# max32665 register map
Vendor: Maxim-Integrated; Series: ARMCM3; File version: 1.0
CPU: CM4 r2p1, little endian, MPU, FPU, 3 interrupt priority bits
Registers are 32-bit, read-write, reset 0x0 unless marked. A register's access mark holds for its fields unless they carry their own. Offsets are from the block's base; [hi:lo] are bit positions; {n}, {i} and the like mark numbered series; 'fields as' and 'values as' point back to an identical list.

## GCR — Global Control Registers.
Base 0x40000000
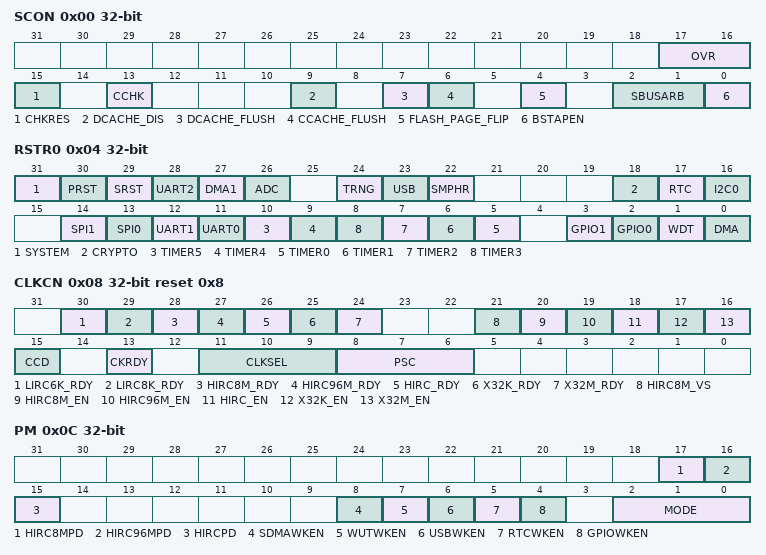
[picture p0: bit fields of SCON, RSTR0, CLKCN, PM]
0x00 SCON (reset mask 0xFFFFFFFE) — System Control.
  [17:16] OVR — Operating Voltage Range. Setting these bits according to the VCore voltage allows the on-chip Random-Access memories to operate in their optimal timing range.
    0=0_9V (0.9V +/- 10%); 1=1_0V (1.0V +/- 10%); 2=1_1V (1.1V +/- 10%)
  [15] CHKRES — ROM Checksum Result. This bit is only valid when CHKRD=1.
    0=pass (ROM Checksum Correct.); 1=fail (ROM Checksum Fail.)
  [13] CCHK — Compute ROM Checksum. This bit is self-cleared when calculation is completed. Once set, software clearing this bit is ignored and the bit will remain set until the operation is completed.
    0=complete (No operation/complete.); 1=Start operation
  [9] DCACHE_DIS — Data Cache Disable. The system cache(s) will be completely disabled when this bit is set.
    0=en (Is enabled.); 1=dis (Is Disabled.)
  [7] DCACHE_FLUSH — Data Cache Flush. The system cache(s) will be flushed when this bit is set.
    0=Normal System Cache Operation; 1=flush (System Cache is flushed)
  [6] CCACHE_FLUSH — Code Cache Flush. This bit is used to flush the code caches and the instruction buffer of the Cortex-M4.
    0=Normal Code Cache Operation; 1=flush (Code Caches and CPU instruction buffer are flushed)
  [4] FLASH_PAGE_FLIP — Flips the Flash bottom and top halves. (Depending on the total flash size, each half is either 256K or 512K). Initiating a flash page flip will cause a flush of both the data buffer on the DCODE bus and the internal instruction buffer.
    0=normal (Physical layout matches logical layout.); 1=swapped (Bottom half mapped to logical top half and vice versa.)
  [2:1] SBUSARB — System bus abritration scheme. These bits are used to select between Fixed-burst abritration and Round-Robin scheme. The Round-Robin scheme is selected by default. These bits are reset by the system reset.
    0=fix (Fixed Burst abritration.); 1=Round-robin scheme
  [0] BSTAPEN — Boundary Scan TAP enable. When enabled, the JTAG port is connected to the Boundary Scan TAP. Otherwise, the port is connected to the ARM ICE function. This bit is reset by the POR. Reset value and access depend on the part number.
    0=dis (Boundary Scan TAP port disabled.); 1=en (Boundary Scan TAP port enabled.)
0x04 RSTR0 — Reset.
  [all] fields
    0=reset_done (Reset complete.); 1=busy (Starts Reset or indicates reset in progress.)
  [31] SYSTEM — System Reset. Setting this bit to 1 resets the CPU core and all peripherals, including the watchdog timer.
  [30] PRST — Peripheral Reset. Setting this bit to 1 resets all peripherals. The CPU core, the watchdog timer, and all GPIO pins are unaffected by this reset.
  [29] SRST — Soft Reset. Setting this bit to 1 resets everything except the CPU and the watchdog timer.
  [28] UART2 — UART2 Reset. Setting this bit to 1 resets all UART 2 blocks.
  [27] DMA1 — DMA 1 Reset.
  [26] ADC — Analog to Digital Reset.
  [24] TRNG — TRNG Reset.
  [23] USB — USB Reset. Setting this bit resets both USB blocks.
  [22] SMPHR — SMPHR Reset. Setting this bit to 1 resets the SMPHR block.
  [18] CRYPTO — Cryptographic Reset. Setting this bit to 1 resets the AES block, the SHA block and the DES block.
  [17] RTC — Real Time Clock Reset.
  [16] I2C0 — I2C0 Reset.
  [14] SPI1 — SPI1 Reset. Setting this bit to 1 resets all SPI 1 blocks.
  [13] SPI0 — SPI0 Reset. Setting this bit to 1 resets all SPI 0 blocks.
  [12] UART1 — UART1 Reset. Setting this bit to 1 resets all UART 1 blocks.
  [11] UART0 — UART0 Reset. Setting this bit to 1 resets all UART 0 blocks.
  [10] TIMER5 — Timer3 Reset. Setting this bit to 1 resets Timer 5 blocks.
  [9] TIMER4 — Timer3 Reset. Setting this bit to 1 resets Timer 4 blocks.
  [n+5] TIMER{n} (n=0..3) — Timer{n} Reset. Setting this bit to 1 resets Timer {n} blocks.
  [3] GPIO1 — GPIO1 Reset. Setting this bit to 1 resets GPIO1 pins to their default states.
  [2] GPIO0 — GPIO0 Reset. Setting this bit to 1 resets GPIO0 pins to their default states.
  [1] WDT — Watchdog Timer Reset.
  [0] DMA — DMA Reset.
0x08 CLKCN reset 0x8 — Clock Control.
  [30] LIRC6K_RDY ro — 6kHz Low Frequency Reference Clock Ready.
    0=not (Is not Ready.); 1=ready (Is Ready.)
  [29] LIRC8K_RDY ro — 8kHz Low Frequency Reference Clock Ready.
    0=not (Is not Ready.); 1=ready (Is Ready.)
  [28] HIRC8M_RDY ro — 8MHz HIRC Ready.
    0=not (Is not Ready.); 1=ready (Is Ready.)
  [27] HIRC96M_RDY ro — 96MHz HIRC Ready.
    0=not (Is not Ready.); 1=ready (Is Ready.)
  [26] HIRC_RDY ro — 60MHz HIRC Ready.
    0=not (Is not Ready.); 1=ready (Is Ready.)
  [25] X32K_RDY ro — 32kHz Crystal Oscillator Ready
    0=not (Is not Ready.); 1=ready (Is Ready.)
  [24] X32M_RDY ro — 32MHz Crystal Oscillator Ready
    0=not (Is not Ready.); 1=ready (Is Ready.)
  [21] HIRC8M_VS — 8MHz High Frequency Internal Reference Clock Voltage Select. This register bit is used to select the power supply to the HIRC8M.
    0=VCore Supply; 1=1V (Dedicated 1v regulated supply.)
  [20] HIRC8M_EN — 8MHz High Frequency Internal Reference Clock Enable.
    0=dis (Is Disabled.); 1=en (Is Enabled.)
  [19] HIRC96M_EN — 96MHz High Frequency Internal Reference Clock Enable.
    0=dis (Is Disabled.); 1=en (Is Enabled.)
  [18] HIRC_EN — 60MHz High Frequency Internal Reference Clock Enable.
    0=dis (Is Disabled.); 1=en (Is Enabled.)
  [17] X32K_EN — 32kHz Crystal Oscillator Enable.
    0=dis (Is Disabled.); 1=en (Is Enabled.)
  [16] X32M_EN — 32MHz Crystal Oscillator Enable.
    0=dis (Is Disabled.); 1=en (Is Enabled.)
  [15] CCD ro — Cryptographic clock divider
    0=non_div (The cryptographic accelerator clock is running in non-divided mode.); 1=div (The cryptographic accelerator clock is running in divided mode.)
  [13] CKRDY ro — Clock Ready. This read only bit reflects whether the currently selected system clock source is running.
    0=busy (Switchover to the new clock source (as selected by CLKSEL) has not yet occurred.); 1=ready (System clock running from CLKSEL clock source.)
  [11:9] CLKSEL — Clock Source Select. This 3 bit field selects the source for the system clock.
    0=HIRC (HIRC Clock); 2=XTAL32M (32MHz Crystal is used for the system clock.); 3=LIRC8 (8kHz LIRC is used for the system clock.); 4=HIRC96 (The internal 96 MHz oscillator is used for the system clock.); 5=HIRC8 (The internal 8 MHz oscillator is used for the system clock.); 6=XTAL32k (32kHz is used for the system clock.)
  [8:6] PSC — Prescaler Select. This 3 bit field sets the system operating frequency by controlling the prescaler that divides the output of the PLL0.
    0=div1 (Divide by 1.); 1=div2 (Divide by 2.); 2=div4 (Divide by 4.); 3=div8 (Divide by 8.); 4=div16 (Divide by 16.); 5=div32 (Divide by 32.); 6=div64 (Divide by 64.); 7=div128 (Divide by 128.)
0x0C PM — Power Management.
  [17] HIRC8MPD — 8MHz power down. This bit selects 8MHz HIRC power state in DEEPSLEEP mode.
    0=active (Mode is Active.); 1=deepsleep (Powered down in DEEPSLEEP.)
  [16] HIRC96MPD — 96MHz power down. This bit selects 96MHz HIRC power state in DEEPSLEEP mode.
    values as HIRC8MPD
  [15] HIRCPD — HIRC Power Down. This bit selects HIRC power state in DEEPSLEEP mode.
    values as HIRC8MPD
  [8] SDMAWKEN — SDMA Wake Up Enable. This bit enables SDMA IRQ activity as wakeup source.
    0=dis (Wake Up Disable.); 1=en (Wake Up Enable.)
  [7] WUTWKEN — WUT Wake Up Enable. This bit enables WUT IRQ as wakeup source.
    0=dis (Wake Up Disable.); 1=en (Wake Up Enable.)
  [6] USBWKEN — USB Wake Up Enable. This bit enables USB activity as wakeup source.
    0=dis (Wake Up Disable.); 1=en (Wake Up Enable.)
  [5] RTCWKEN — RTC Alarm Wake Up Enable. This bit enables RTC alarm as wakeup source. If enabled, the desired RTC alarm must be configured via the RTC control registers.
    0=dis (Wake Up Disable.); 1=en (Wake Up Enable.)
  [4] GPIOWKEN — GPIO Wake Up Enable. This bit enables all GPIO pins as potential wakeup sources. Any GPIO configured for wakeup is capable of causing an exit from IDLE or STANDBY modes when this bit is set.
    0=dis (Wake Up Disable.); 1=en (Wake Up Enable.)
  [2:0] MODE — Operating Mode. This two bit field selects the current operating mode for the device. Note that code execution only occurs during ACTIVE mode.
    0=Active Mode; 2=DeepSleep Mode; 3=Shutdown Mode; 4=Backup Mode
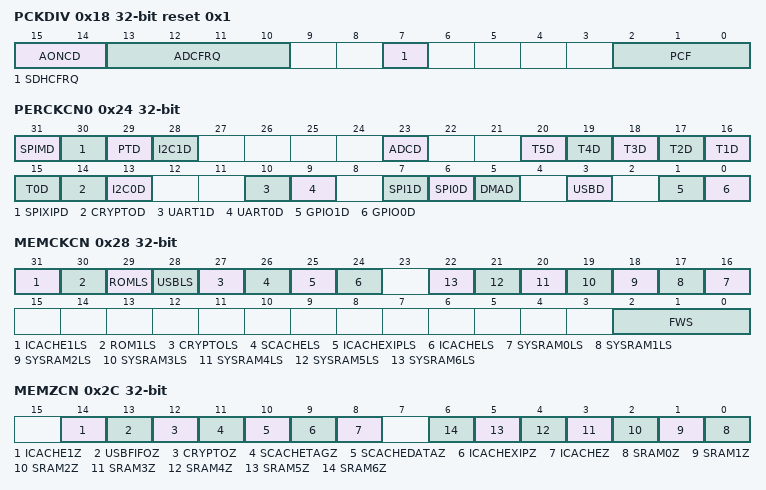
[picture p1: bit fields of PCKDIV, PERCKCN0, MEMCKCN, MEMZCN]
0x18 PCKDIV reset 0x1 — Peripheral Clock Divider.
  [15:14] AONCD — Always-ON(AON) domain CLock Divider. These bits define the AON domain clock divider.
    0=div_4 (PCLK divide by 4.); 1=div_8 (PCLK divide by 8.); 2=div_16 (PCLK divide by 16.); 3=div_32 (PCLK divide by 32.)
  [13:10] ADCFRQ — ADC clock Frequency. These bits define the ADC clock frequency. FADC = FPCLK/(ADCFRQ).
  [7] SDHCFRQ — SDHC Clock Frequency. This bits defines the clock frequency of SDHC.
    0=48MHz; 1=24MHz
  [2:0] PCF — These bits determine the clock frequency for the UART, I2C and Key Pad peripherals. These peripherals have an adaptive clock generator that dynamically adjusts the peripheral frequency based on the main system bus frequency. These bits are dynamically updated when the PLL0 is selected as the system clock source and are set by hardware. These bits determine the clock frequency for the UART, I2C and Key Pad peripherals. These peripherals have an adaptive clock generator that dynamically adjusts the peripheral frequency based on the main system bus frequency. These bits are dynamically updated when the PLL0 is selected as the system clock source and are set by hardware.
    2=96MHz; 3=48MHz; 4=24MHz; 5=12MHz; 6=6MHz; 7=3MHz
0x24 PERCKCN0 — Peripheral Clock Disable.
  [all] fields
    0=en (enable it.); 1=dis (disable it.)
  [31] SPIMD — SPI XiP Master Controller Disable.
  [30] SPIXIPD — SPI XiP Disable.
  [29] PTD — PT Clock Disable.
  [28] I2C1D — I2C 1 Disable.
  [23] ADCD — ADC Disable.
  [n+15] T{n}D (n=0..5) — Timer {n} Disable.
  [14] CRYPTOD — Crypto Disable.
  [13] I2C0D — I2C 0 Disable.
  [10] UART1D — UART 1 Disable.
  [9] UART0D — UART 0 Disable.
  [7] SPI1D — SPI 1 Disable.
  [6] SPI0D — SPI 0 Disable.
  [5] DMAD — DMA Disable.
  [3] USBD — USB Disable.
  [1] GPIO1D — GPIO1 Disable.
  [0] GPIO0D — GPIO0 Disable.
0x28 MEMCKCN — Memory Clock Control Register.
  [31] ICACHE1LS — ICache RAM Light Sleep Mode.
    0=active (RAM is active.); 1=light_sleep (RAM is in Light Sleep mode.)
  [30] ROM1LS — ROM1 Light Sleep Mode.
    values as ICACHE1LS
  [29] ROMLS — ROM Light Sleep Mode.
    values as ICACHE1LS
  [28] USBLS — USB FIFO Light Sleep Mode.
    values as ICACHE1LS
  [27] CRYPTOLS — CRYPTO RAM Light Sleep Mode.
    values as ICACHE1LS
  [26] SCACHELS — SysCache RAM Light Sleep Mode.
    values as ICACHE1LS
  [25] ICACHEXIPLS — ICACHE-XIP RAM Light Sleep Mode.
    values as ICACHE1LS
  [24] ICACHELS — ICache RAM Light Sleep Mode.
    values as ICACHE1LS
  [n+16] SYSRAM{n}LS (n=0..6) — System RAM {n} Light Sleep Mode.
    values as ICACHE1LS
  [2:0] FWS — Flash Wait State. These bits define the number of wait-state cycles per Flash data read access. Minimum wait state is 2.
0x2C MEMZCN — Memory Zeroize Control.
  [all] fields
    0=nop (No operation/complete.); 1=Start operation
  [14] ICACHE1Z — Instruction Cache.
  [13] USBFIFOZ — USB FIFO Zeroizatoin.
  [12] CRYPTOZ — Crypto (MAA) Memory.
  [11] SCACHETAGZ — System Cache Tag Zeroization.
  [10] SCACHEDATAZ — System Cache Data Ram Zeroization.
  [9] ICACHEXIPZ — Instruction Cache XIP Data and Tag Ram zeroizatoin.
  [8] ICACHEZ — Instruction Cache.
  [n] SRAM{n}Z (n=0..6) — System RAM Block {n}.
0x34 SCCK reset 0x1414 — Smart Card Clock Control.
0x38 MPRI0 reset 0x1414 — Master Priority Control Register 0.
0x3C MPRI1 reset 0x1414 — Mater Priority Control Register 1.
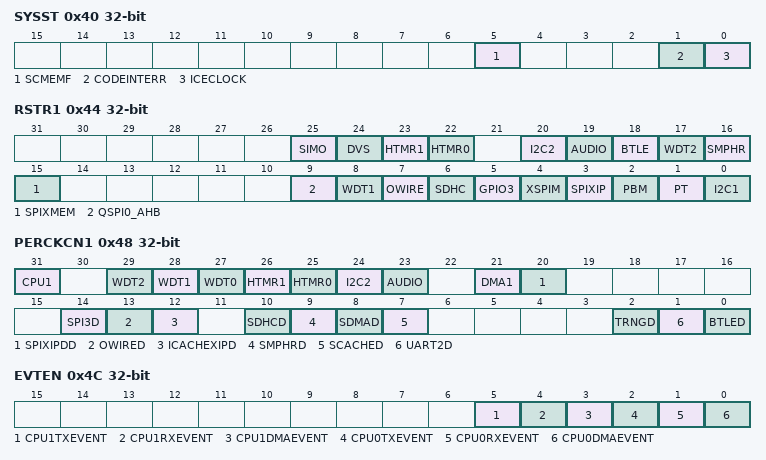
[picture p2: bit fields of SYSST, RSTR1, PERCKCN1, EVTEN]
0x40 SYSST — System Status Register.
  [5] SCMEMF — System Cache Memory Fault Flag. This bit indicates a memory fault has occured in the System Cache while receiving data from the Hyperbus Interface.
    0=Normal Operating Condition; 1=Memory Fault
  [1] CODEINTERR — Code Integrity Error Flag. This bit indicates a code integrity error has occured in XiP interface.
    0=Normal Operating Condition; 1=Code Integrity Error
  [0] ICECLOCK — ARM ICE Lock Status.
    0=unlocked (ICE is unlocked.); 1=locked (ICE is locked.)
0x44 RSTR1 — Reset 1.
  [all] fields
    on read: 0=reset_done (Reset complete.); 1=busy (Starts reset or indicates reset in progress.)
  [25] SIMO — SIMO Reset.
  [24] DVS — DVS Reset.
  [23] HTMR1 — HTMR1 Reset.
  [22] HTMR0 — HTMR0 Reset.
  [20] I2C2 — I2C2 Reset.
  [19] AUDIO — AUDIO Reset.
  [18] BTLE — BTLE Reset.
  [17] WDT2 — WDT2 Reset.
  [16] SMPHR — SMPHR Reset.
  [15] SPIXMEM — SPIXMEM Reset.
  [9] QSPI0_AHB — QSPI0_AHB Reset.
  [8] WDT1 — WDT1 Reset.
  [7] OWIRE — OWIRE Reset.
  [6] SDHC — SDHC/SDIO Reset.
  [5] GPIO3 — GPIO3 Reset.
  [4] XSPIM — GSPI XiP Master Controller Reset.
  [3] SPIXIP — SPI XiP Master Reset.
  [2] PBM — PBM Reset.
  [1] PT — PT Reset.
  [0] I2C1 — I2C1 Reset.
0x48 PERCKCN1 — Peripheral Clock Disable.
  [all] fields
    0=en (Enable.); 1=dis (Disable.)
  [31] CPU1 — CPU1 Clock Disable
  [29] WDT2 — WDT2 Clock Disable
  [28] WDT1 — WDT1 Clock Disable
  [27] WDT0 — WDT0 Clock Disable
  [26] HTMR1 — HTMR 1 Clock Disable
  [25] HTMR0 — HTMR 0 Clock Disable
  [24] I2C2 — I2C 2 Clock Disable
  [23] AUDIO — AUDIO Clock Disable
  [21] DMA1 — DMA1 Clock Disable
  [20] SPIXIPDD — SPI-XIP Data Clock Disable
  [14] SPI3D — SPI3 Clock Disable.
  [13] OWIRED — One-Wire Clock Disable.
  [12] ICACHEXIPD — ICache XIP Clock Disable.
  [10] SDHCD — SDHC/SDIO Clock Disable.
  [9] SMPHRD — Semaphore Clock Disable.
  [8] SDMAD — SDMA Clock Disable.
  [7] SCACHED — System Cache Clock Disable.
  [2] TRNGD — TRNG Disable.
  [1] UART2D — UART2 Disable.
  [0] BTLED — BTLE Disable.
0x4C EVTEN — Event Enable Register.
  [5] CPU1TXEVENT — Enable TXEV pin event. When this bit is set, TXEV event from the CPU is output to GPIO[25].
  [4] CPU1RXEVENT — Enable RXEV pin event. When this bit is set, a logic high of GPIO0[24] will cause an RXEV event to wake the CPU from WFE sleep mode.
  [3] CPU1DMAEVENT — Enable DMA event. When this bit is set, a DMA event will cause an RXEV event to wake the CPU from WFE sleep mode.
  [2] CPU0TXEVENT — Enable TXEV pin event. When this bit is set, TXEV event from the CPU is output to GPIO[25].
  [1] CPU0RXEVENT — Enable RXEV pin event. When this bit is set, a logic high of GPIO0[24] will cause an RXEV event to wake the CPU from WFE sleep mode.
  [0] CPU0DMAEVENT — Enable DMA event. When this bit is set, a DMA event will cause an RXEV event to wake the CPU from WFE sleep mode.
0x50 REVISION ro
  [15:0] REVISION — Manufacturer Chip Revision.
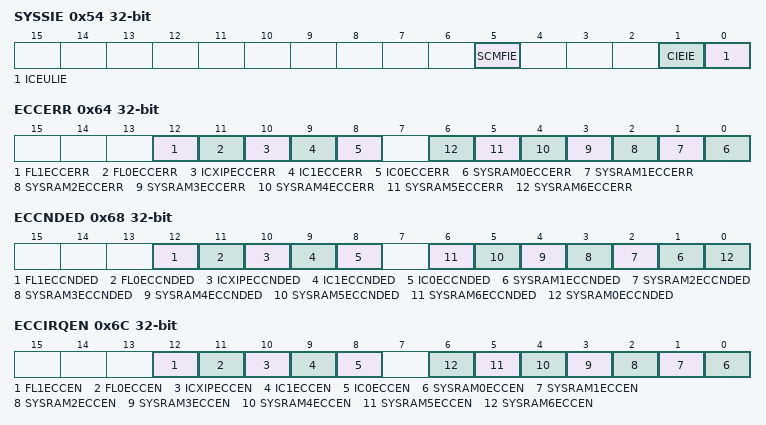
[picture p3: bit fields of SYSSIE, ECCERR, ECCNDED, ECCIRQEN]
0x54 SYSSIE — System Status Interrupt Enable Register.
  [all] fields
    0=dis (disabled.); 1=en (enabled.)
  [5] SCMFIE — System Cache Memory Fault Interrupt Enable.
  [1] CIEIE — Code Integrity Error Interrupt Enable.
  [0] ICEULIE — ARM ICE Unlock Interrupt Enable.
0x64 ECCERR — ECC Error Register
  [12] FL1ECCERR — ECC Flash1 Error Flag. Write 1 to clear.
  [11] FL0ECCERR — ECC Flash0 Error Flag. Write 1 to clear.
  [10] ICXIPECCERR — ECC IcacheXIP Error Flag. Write 1 to clear.
  [9] IC1ECCERR — ECC Icache1 Error Flag. Write 1 to clear.
  [8] IC0ECCERR — ECC Icache0 Error Flag. Write 1 to clear.
  [n] SYSRAM{n}ECCERR (n=0..6) — ECC System RAM{n} Error Flag. Write 1 to clear.
0x68 ECCNDED — ECC Not Double Error Detect Register
  [12] FL1ECCNDED — ECC Flash1 Not Double Error Detect. Write 1 to clear.
  [11] FL0ECCNDED — ECC Flash0 Not Double Error Detect. Write 1 to clear.
  [10] ICXIPECCNDED — ECC IcacheXIP Not Double Error Detect. Write 1 to clear.
  [9] IC1ECCNDED — ECC Icache1 Not Double Error Detect. Write 1 to clear.
  [8] IC0ECCNDED — ECC Icache0 Not Double Error Detect. Write 1 to clear.
  [n] SYSRAM{n}ECCNDED (n=1..6) — ECC System RAM{n} Not Double Error Detect. Write 1 to clear.
  [0] SYSRAM0ECCNDED — ECC System RAM0 Error Flag. Write 1 to clear.
0x6C ECCIRQEN — ECC IRQ Enable Register
  [12] FL1ECCEN — ECC Flash1 NError Interrup Enable
  [11] FL0ECCEN — ECC Flash0 NError Interrup Enable
  [10] ICXIPECCEN — ECC IcacheXIP Error Interrup Enable
  [9] IC1ECCEN — ECC Icache1 Error Interrup Enable
  [8] IC0ECCEN — ECC Icache0 Error Interrup Enable
  [n] SYSRAM{n}ECCEN (n=0..6) — ECC System RAM{n} Error Interrup Enable
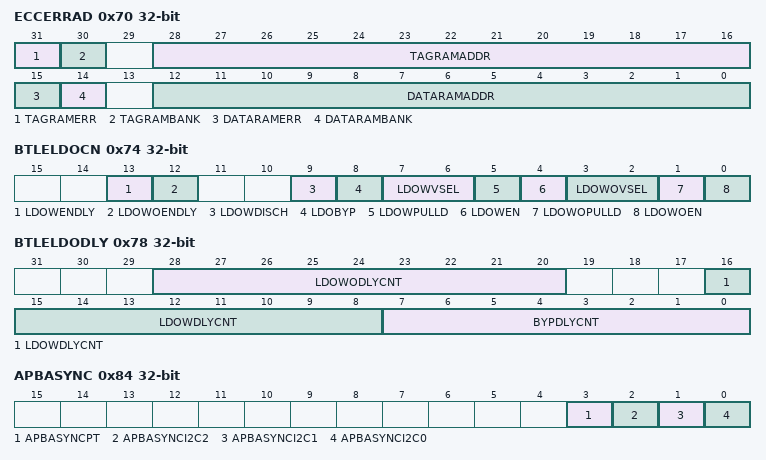
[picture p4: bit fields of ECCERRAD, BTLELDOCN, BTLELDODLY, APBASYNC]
0x70 ECCERRAD — ECC Error Address Register
  [31] TAGRAMERR — ECC Error Address.Tag Ram Error.
  [30] TAGRAMBANK — ECC Error Address.Tag Ram Bank.
  [28:16] TAGRAMADDR — ECC Error Address.Tag Ram Address.
  [15] DATARAMERR — ECC Error Address.Data Ram Error.
  [14] DATARAMBANK — ECC Error Address.Data Error Bank.
  [12:0] DATARAMADDR — ECC Error Address.Data Ram Address.
0x74 BTLELDOCN — BTLE LDO Control Register
  [13] LDOWENDLY — LDOW Enable Delay Status
    0=dis (disabled.); 1=en (enabled.)
  [12] LDOWOENDLY — LDOWO Enable Delay Status
    0=dis (disabled.); 1=en (enabled.)
  [9] LDOWDISCH — LDOW Discharge
    0=dis (disabled.); 1=en (enabled.)
  [8] LDOBYP — LDO Bypass Enable
    0=dis (disabled.); 1=en (enabled.)
  [7:6] LDOWVSEL — LDOW Voltage Setting
    0=0_7 (0.7V); 1=0.85V; 2=0_9 (0.9V); 3=1.1V
  [5] LDOWPULLD — LDOW PULL Disable
    0=en (enabled.); 1=dis (disabled.)
  [4] LDOWEN — LDOW Enable
    0=dis (disabled.); 1=en (enabled.)
  [3:2] LDOWOVSEL — LDOWO Voltage Setting
    0=0_7 (0.7V); 1=0.85V; 2=0_9 (0.9V); 3=1.1V
  [1] LDOWOPULLD — LDOWO PULL Disable
    0=en (enabled.); 1=dis (disabled.)
  [0] LDOWOEN — LDOWO Enable
    0=dis (disabled.); 1=en (enabled.)
0x78 BTLELDODLY — BTLE LDO Delay Register
  [28:20] LDOWODLYCNT — LDOWO Delay Count. Count delay base on PCLK/128.
  [16:8] LDOWDLYCNT — LDOW Delay Count. Count delay base on PCLK/128.
  [7:0] BYPDLYCNT — Bypass Delay Count. Count delay base on PCLK.
0x80 GP0 — General Purpose Register 0
0x84 APBASYNC — APB Asynchronous Bridge Select Register
  [all] fields
    0=PCLK Source; 1=7mclk (7.37MHz Source)
  [3] APBASYNCPT — Feeds PT with either PCLK or 7.37MHz Clk
  [2] APBASYNCI2C2 — Feeds I2C2 with either PCLK or 7.37MHz Clk
  [1] APBASYNCI2C1 — Feeds I2C1 with either PCLK or 7.37MHz Clk
  [0] APBASYNCI2C0 — Feeds I2C0 with either PCLK or 7.37MHz Clk
